AUTOSAR XML (schema 4-2-2)
package /ComponentTypes
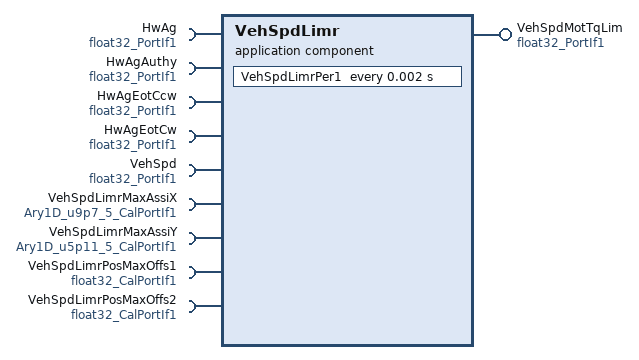
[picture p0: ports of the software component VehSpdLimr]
  application sw component type VehSpdLimr
    provide port VehSpdMotTqLim: nonqueued-sender-com-spec{data-element=Val, init-value=0}, provided-interface=float32_PortIf1
    9 x require port:
      HwAg: nonqueued-receiver-com-spec{data-element=Val, filter=data-filter-type=ALWAYS, init-value=0}, required-interface=float32_PortIf1
      HwAgAuthy: nonqueued-receiver-com-spec{data-element=Val, filter=data-filter-type=ALWAYS, init-value=0}, required-interface=float32_PortIf1
      HwAgEotCcw: nonqueued-receiver-com-spec{data-element=Val, filter=data-filter-type=ALWAYS, init-value=-360}, required-interface=float32_PortIf1
      HwAgEotCw: nonqueued-receiver-com-spec{data-element=Val, filter=data-filter-type=ALWAYS, init-value=360}, required-interface=float32_PortIf1
      VehSpd: nonqueued-receiver-com-spec{data-element=Val, filter=data-filter-type=ALWAYS, init-value=0}, required-interface=float32_PortIf1
      VehSpdLimrMaxAssiX: parameter-require-com-spec{init-value=[0, 3200, 6400, 8320, 9600], parameter=Ary1D}, required-interface=Ary1D_u9p7_5_CalPortIf1
      VehSpdLimrMaxAssiY: parameter-require-com-spec{init-value=5 x 18022, parameter=Ary1D}, required-interface=Ary1D_u5p11_5_CalPortIf1
      VehSpdLimrPosMaxOffs1: parameter-require-com-spec{init-value=140, parameter=Val}, required-interface=float32_CalPortIf1
      VehSpdLimrPosMaxOffs2: parameter-require-com-spec{init-value=120, parameter=Val}, required-interface=float32_CalPortIf1
    behavior VehSpdLimr_InternalBehavior
      ar-typed-per-instance-memorys:
        4 x data, all with sw-calibration-access=READ-ONLY:
          dVehSpdLimrBreakPt1: type=float32
          dVehSpdLimrBreakPt2: type=float32
          dVehSpdLimrLimTerm: type=u5p11
          dVehSpdLimrZeroVehSpd: type=u5p11
      timing event TMT_VehSpdLimrPer1: start-on-event=VehSpdLimrPer1, period=0.002
      runnable VehSpdLimrPer1
        data-receive-point-by-arguments:
          5 x access:
            REC_HwAg_Val: accessed-variable=HwAg.Val
            REC_HwAgAuthy_Val: accessed-variable=HwAgAuthy.Val
            REC_HwAgEotCcw_Val: accessed-variable=HwAgEotCcw.Val
            REC_HwAgEotCw_Val: accessed-variable=HwAgEotCw.Val
            REC_VehSpd_Val: accessed-variable=VehSpd.Val
        data-send-points:
          access SEND_VehSpdMotTqLim_Val: accessed-variable=VehSpdMotTqLim.Val
  swc implementation VehSpdLimr_Implementation: behavior=VehSpdLimr_InternalBehavior
    code-descriptors:
      code Default: artifact-descriptors=autosar-engineering-object={short-label=Default, category=SWSRC}
